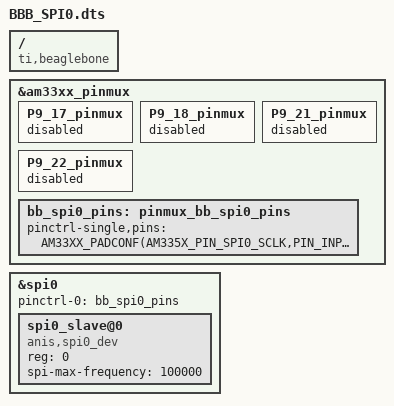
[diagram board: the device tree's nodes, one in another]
/dts-v1/;
/plugin/;

#include <dt-bindings/gpio/gpio.h>
#include <dt-bindings/pinctrl/am33xx.h>
#include <dt-bindings/interrupt-controller/irq.h>

/ {
	compatible = "ti,beaglebone", "ti,beaglebone-black";
	
	fragment@0 {
		target = <&am33xx_pinmux>;
		__overlay__ {
			P9_17_pinmux {
                status = "disabled";
            };
            P9_18_pinmux {
                status = "disabled";
            };
            P9_21_pinmux {
                status = "disabled";
            };
            P9_22_pinmux {
                status = "disabled";
            };
			
			bb_spi0_pins: pinmux_bb_spi0_pins {
				pinctrl-single,pins = <
					AM33XX_PADCONF(AM335X_PIN_SPI0_SCLK,PIN_INPUT, MUX_MODE0)	// P9_22 (A17) spi0_sclk
					AM33XX_PADCONF(AM335X_PIN_SPI0_D0, 	PIN_INPUT, MUX_MODE0)	// P9_21 (B17) spi0_d0
					AM33XX_PADCONF(AM335X_PIN_SPI0_D1, 	PIN_INPUT, MUX_MODE0)	// P9_18 (B16) spi0_d1
					AM33XX_PADCONF(AM335X_PIN_SPI0_CS0, PIN_INPUT, MUX_MODE0)	// P9_17 (A16) spi0_cs0
				>;
			};
		};
	};

	fragment@1 {
		target = <&spi0>;
		__overlay__ {
			status = "okay";
			pinctrl-names = "default";
			pinctrl-0 = <&bb_spi0_pins>;
			
			spi0_slave@0 {
				#address-cells = <1>;
				#size-cells = <0>;

				compatible = "anis,spi0_dev";
				reg = <0>;
				spi-max-frequency = <100000>;
			};
		};
	};
};
